# ESP32-C61 register map
Vendor: ESPRESSIF SYSTEMS (SHANGHAI) CO., LTD.; Series: ESP32 C-Series; File version: 1
CPU: RV32IMAC r0p0, little endian, no MPU, no FPU, 0 interrupt priority bits
Address unit: 32 bits
Registers are 32-bit, read-write, reset 0x0 unless marked. A register's access mark holds for its fields unless they carry their own. Offsets are from the block's base; [hi:lo] are bit positions; lines under a group give offsets from that group; {n}, {i} and the like mark numbered series.

## SOC_ETM — Event Task Matrix
Base 0x60013000
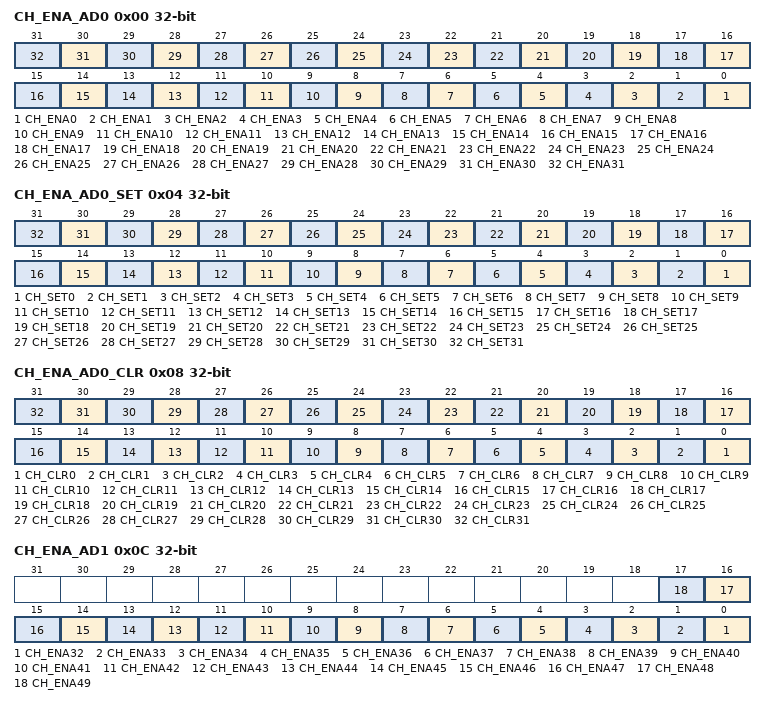
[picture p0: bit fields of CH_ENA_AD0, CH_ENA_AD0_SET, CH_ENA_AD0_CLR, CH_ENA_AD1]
0x00 CH_ENA_AD0 — Channel enable status register
  [n] CH_ENA{n} (n=0..31) — Represents ch{n} enable status.\\0: Disable\\1: Enable
0x04 CH_ENA_AD0_SET wo — Channel enable set register
  [n] CH_SET{n} (n=0..31) — Configures whether or not to enable ch{n}.\\0: Invalid, No effect\\1: Enable
0x08 CH_ENA_AD0_CLR wo — Channel enable clear register
  [n] CH_CLR{n} (n=0..31) — Configures whether or not to clear ch{n} enable.\\0: Invalid, No effect\\1: Clear
0x0C CH_ENA_AD1 — Channel enable status register
  [n-32] CH_ENA{n} (n=32..49) — Represents ch{n} enable status.\\0: Disable\\1: Enable
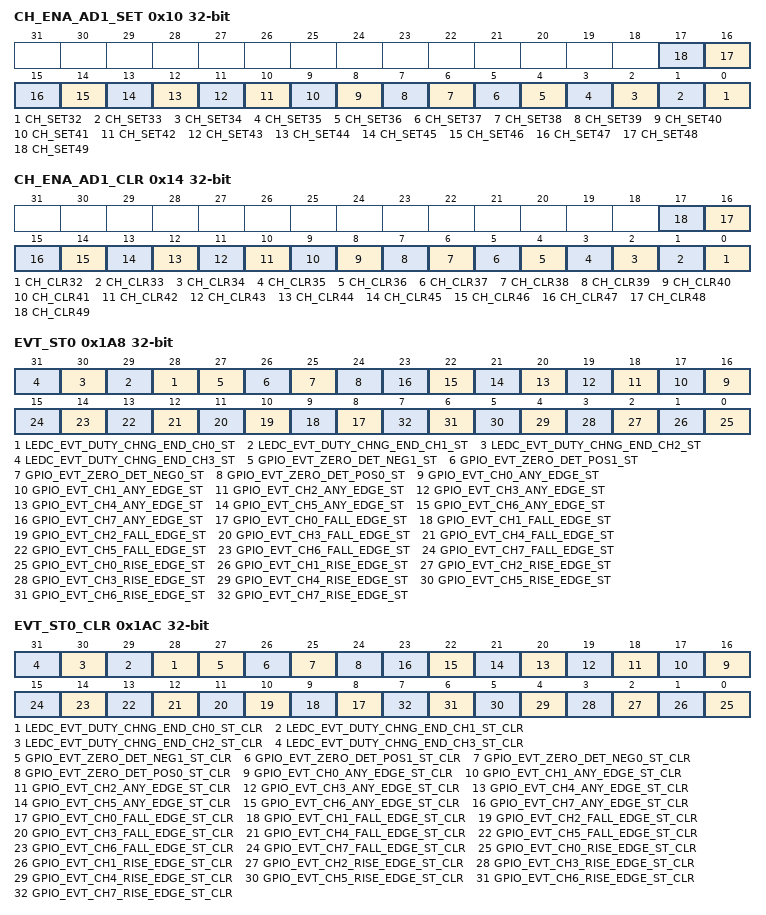
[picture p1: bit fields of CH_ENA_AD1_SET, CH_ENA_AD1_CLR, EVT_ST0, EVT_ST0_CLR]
0x10 CH_ENA_AD1_SET wo — Channel enable set register
  [n-32] CH_SET{n} (n=32..49) — Configures whether or not to enable ch{n}.\\0: Invalid, No effect\\1: Enable
0x14 CH_ENA_AD1_CLR wo — Channel enable clear register
  [n-32] CH_CLR{n} (n=32..49) — Configures whether or not to clear ch{n} enable.\\0: Invalid, No effect\\1: Clear
{0x18+8i} CH{i} (i=0..49) group — Cluster CH{i}, containing CH*_EVT_ID, CH*_TASK_ID
  0x00 EVT_ID — Channel0 event id register
    [6:0] EVT_ID — Configures ch0_evt_id
  0x04 TASK_ID — Channel0 task id register
    [7:0] TASK_ID — Configures ch0_task_id
0x1A8 EVT_ST0 — Events trigger status register
  [n+28] LEDC_EVT_DUTY_CHNG_END_CH{n}_ST (n=0..3) — Represents LEDC_evt_duty_chng_end_ch{n} trigger status.\\0: Not triggered\\1: Triggered
  [27] GPIO_EVT_ZERO_DET_NEG1_ST — Represents GPIO_evt_zero_det_neg1 trigger status.\\0: Not triggered\\1: Triggered
  [26] GPIO_EVT_ZERO_DET_POS1_ST — Represents GPIO_evt_zero_det_pos1 trigger status.\\0: Not triggered\\1: Triggered
  [25] GPIO_EVT_ZERO_DET_NEG0_ST — Represents GPIO_evt_zero_det_neg0 trigger status.\\0: Not triggered\\1: Triggered
  [24] GPIO_EVT_ZERO_DET_POS0_ST — Represents GPIO_evt_zero_det_pos0 trigger status.\\0: Not triggered\\1: Triggered
  [n+16] GPIO_EVT_CH{n}_ANY_EDGE_ST (n=0..7) — Represents GPIO_evt_ch{n}_any_edge trigger status.\\0: Not triggered\\1: Triggered
  [n+8] GPIO_EVT_CH{n}_FALL_EDGE_ST (n=0..7) — Represents GPIO_evt_ch{n}_fall_edge trigger status.\\0: Not triggered\\1: Triggered
  [n] GPIO_EVT_CH{n}_RISE_EDGE_ST (n=0..7) — Represents GPIO_evt_ch{n}_rise_edge trigger status.\\0: Not triggered\\1: Triggered
0x1AC EVT_ST0_CLR wo — Events trigger status clear register
  [n+28] LEDC_EVT_DUTY_CHNG_END_CH{n}_ST_CLR (n=0..3) — Configures whether or not to clear LEDC_evt_duty_chng_end_ch{n} trigger status.\\0: Invalid, No effect\\1: Clear
  [27] GPIO_EVT_ZERO_DET_NEG1_ST_CLR — Configures whether or not to clear GPIO_evt_zero_det_neg1 trigger status.\\0: Invalid, No effect\\1: Clear
  [26] GPIO_EVT_ZERO_DET_POS1_ST_CLR — Configures whether or not to clear GPIO_evt_zero_det_pos1 trigger status.\\0: Invalid, No effect\\1: Clear
  [25] GPIO_EVT_ZERO_DET_NEG0_ST_CLR — Configures whether or not to clear GPIO_evt_zero_det_neg0 trigger status.\\0: Invalid, No effect\\1: Clear
  [24] GPIO_EVT_ZERO_DET_POS0_ST_CLR — Configures whether or not to clear GPIO_evt_zero_det_pos0 trigger status.\\0: Invalid, No effect\\1: Clear
  [n+16] GPIO_EVT_CH{n}_ANY_EDGE_ST_CLR (n=0..7) — Configures whether or not to clear GPIO_evt_ch{n}_any_edge trigger status.\\0: Invalid, No effect\\1: Clear
  [n+8] GPIO_EVT_CH{n}_FALL_EDGE_ST_CLR (n=0..7) — Configures whether or not to clear GPIO_evt_ch{n}_fall_edge trigger status.\\0: Invalid, No effect\\1: Clear
  [n] GPIO_EVT_CH{n}_RISE_EDGE_ST_CLR (n=0..7) — Configures whether or not to clear GPIO_evt_ch{n}_rise_edge trigger status.\\0: Invalid, No effect\\1: Clear
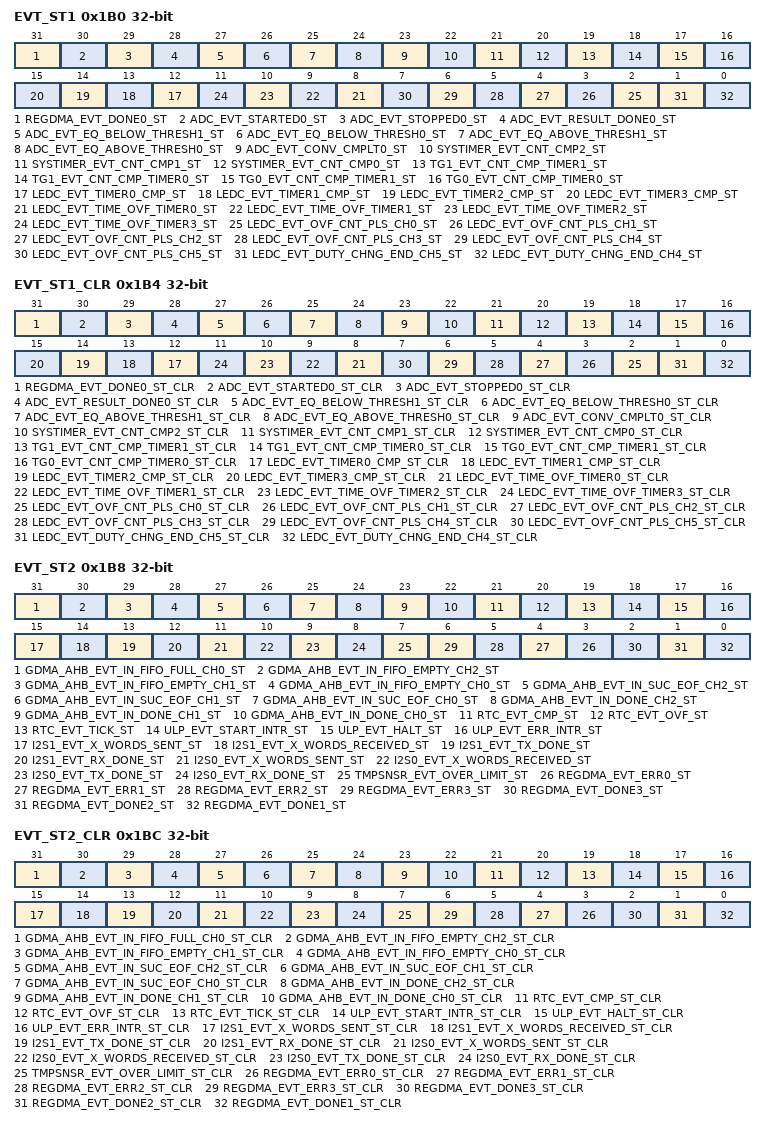
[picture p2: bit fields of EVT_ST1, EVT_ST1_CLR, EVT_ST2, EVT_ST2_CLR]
0x1B0 EVT_ST1 — Events trigger status register
  [31] REGDMA_EVT_DONE0_ST — Represents REGDMA_evt_done0 trigger status.\\0: Not triggered\\1: Triggered
  [30] ADC_EVT_STARTED0_ST — Represents ADC_evt_started0 trigger status.\\0: Not triggered\\1: Triggered
  [29] ADC_EVT_STOPPED0_ST — Represents ADC_evt_stopped0 trigger status.\\0: Not triggered\\1: Triggered
  [28] ADC_EVT_RESULT_DONE0_ST — Represents ADC_evt_result_done0 trigger status.\\0: Not triggered\\1: Triggered
  [27] ADC_EVT_EQ_BELOW_THRESH1_ST — Represents ADC_evt_eq_below_thresh1 trigger status.\\0: Not triggered\\1: Triggered
  [26] ADC_EVT_EQ_BELOW_THRESH0_ST — Represents ADC_evt_eq_below_thresh0 trigger status.\\0: Not triggered\\1: Triggered
  [25] ADC_EVT_EQ_ABOVE_THRESH1_ST — Represents ADC_evt_eq_above_thresh1 trigger status.\\0: Not triggered\\1: Triggered
  [24] ADC_EVT_EQ_ABOVE_THRESH0_ST — Represents ADC_evt_eq_above_thresh0 trigger status.\\0: Not triggered\\1: Triggered
  [23] ADC_EVT_CONV_CMPLT0_ST — Represents ADC_evt_conv_cmplt0 trigger status.\\0: Not triggered\\1: Triggered
  [22] SYSTIMER_EVT_CNT_CMP2_ST — Represents SYSTIMER_evt_cnt_cmp2 trigger status.\\0: Not triggered\\1: Triggered
  [21] SYSTIMER_EVT_CNT_CMP1_ST — Represents SYSTIMER_evt_cnt_cmp1 trigger status.\\0: Not triggered\\1: Triggered
  [20] SYSTIMER_EVT_CNT_CMP0_ST — Represents SYSTIMER_evt_cnt_cmp0 trigger status.\\0: Not triggered\\1: Triggered
  [19] TG1_EVT_CNT_CMP_TIMER1_ST — Represents TG1_evt_cnt_cmp_timer1 trigger status.\\0: Not triggered\\1: Triggered
  [18] TG1_EVT_CNT_CMP_TIMER0_ST — Represents TG1_evt_cnt_cmp_timer0 trigger status.\\0: Not triggered\\1: Triggered
  [17] TG0_EVT_CNT_CMP_TIMER1_ST — Represents TG0_evt_cnt_cmp_timer1 trigger status.\\0: Not triggered\\1: Triggered
  [16] TG0_EVT_CNT_CMP_TIMER0_ST — Represents TG0_evt_cnt_cmp_timer0 trigger status.\\0: Not triggered\\1: Triggered
  [n+12] LEDC_EVT_TIMER{n}_CMP_ST (n=0..3) — Represents LEDC_evt_timer{n}_cmp trigger status.\\0: Not triggered\\1: Triggered
  [n+8] LEDC_EVT_TIME_OVF_TIMER{n}_ST (n=0..3) — Represents LEDC_evt_time_ovf_timer{n} trigger status.\\0: Not triggered\\1: Triggered
  [n+2] LEDC_EVT_OVF_CNT_PLS_CH{n}_ST (n=0..5) — Represents LEDC_evt_ovf_cnt_pls_ch{n} trigger status.\\0: Not triggered\\1: Triggered
  [1] LEDC_EVT_DUTY_CHNG_END_CH5_ST — Represents LEDC_evt_duty_chng_end_ch5 trigger status.\\0: Not triggered\\1: Triggered
  [0] LEDC_EVT_DUTY_CHNG_END_CH4_ST — Represents LEDC_evt_duty_chng_end_ch4 trigger status.\\0: Not triggered\\1: Triggered
0x1B4 EVT_ST1_CLR wo — Events trigger status clear register
  [31] REGDMA_EVT_DONE0_ST_CLR — Configures whether or not to clear REGDMA_evt_done0 trigger status.\\0: Invalid, No effect\\1: Clear
  [30] ADC_EVT_STARTED0_ST_CLR — Configures whether or not to clear ADC_evt_started0 trigger status.\\0: Invalid, No effect\\1: Clear
  [29] ADC_EVT_STOPPED0_ST_CLR — Configures whether or not to clear ADC_evt_stopped0 trigger status.\\0: Invalid, No effect\\1: Clear
  [28] ADC_EVT_RESULT_DONE0_ST_CLR — Configures whether or not to clear ADC_evt_result_done0 trigger status.\\0: Invalid, No effect\\1: Clear
  [27] ADC_EVT_EQ_BELOW_THRESH1_ST_CLR — Configures whether or not to clear ADC_evt_eq_below_thresh1 trigger status.\\0: Invalid, No effect\\1: Clear
  [26] ADC_EVT_EQ_BELOW_THRESH0_ST_CLR — Configures whether or not to clear ADC_evt_eq_below_thresh0 trigger status.\\0: Invalid, No effect\\1: Clear
  [25] ADC_EVT_EQ_ABOVE_THRESH1_ST_CLR — Configures whether or not to clear ADC_evt_eq_above_thresh1 trigger status.\\0: Invalid, No effect\\1: Clear
  [24] ADC_EVT_EQ_ABOVE_THRESH0_ST_CLR — Configures whether or not to clear ADC_evt_eq_above_thresh0 trigger status.\\0: Invalid, No effect\\1: Clear
  [23] ADC_EVT_CONV_CMPLT0_ST_CLR — Configures whether or not to clear ADC_evt_conv_cmplt0 trigger status.\\0: Invalid, No effect\\1: Clear
  [22] SYSTIMER_EVT_CNT_CMP2_ST_CLR — Configures whether or not to clear SYSTIMER_evt_cnt_cmp2 trigger status.\\0: Invalid, No effect\\1: Clear
  [21] SYSTIMER_EVT_CNT_CMP1_ST_CLR — Configures whether or not to clear SYSTIMER_evt_cnt_cmp1 trigger status.\\0: Invalid, No effect\\1: Clear
  [20] SYSTIMER_EVT_CNT_CMP0_ST_CLR — Configures whether or not to clear SYSTIMER_evt_cnt_cmp0 trigger status.\\0: Invalid, No effect\\1: Clear
  [19] TG1_EVT_CNT_CMP_TIMER1_ST_CLR — Configures whether or not to clear TG1_evt_cnt_cmp_timer1 trigger status.\\0: Invalid, No effect\\1: Clear
  [18] TG1_EVT_CNT_CMP_TIMER0_ST_CLR — Configures whether or not to clear TG1_evt_cnt_cmp_timer0 trigger status.\\0: Invalid, No effect\\1: Clear
  [17] TG0_EVT_CNT_CMP_TIMER1_ST_CLR — Configures whether or not to clear TG0_evt_cnt_cmp_timer1 trigger status.\\0: Invalid, No effect\\1: Clear
  [16] TG0_EVT_CNT_CMP_TIMER0_ST_CLR — Configures whether or not to clear TG0_evt_cnt_cmp_timer0 trigger status.\\0: Invalid, No effect\\1: Clear
  [n+12] LEDC_EVT_TIMER{n}_CMP_ST_CLR (n=0..3) — Configures whether or not to clear LEDC_evt_timer{n}_cmp trigger status.\\0: Invalid, No effect\\1: Clear
  [n+8] LEDC_EVT_TIME_OVF_TIMER{n}_ST_CLR (n=0..3) — Configures whether or not to clear LEDC_evt_time_ovf_timer{n} trigger status.\\0: Invalid, No effect\\1: Clear
  [n+2] LEDC_EVT_OVF_CNT_PLS_CH{n}_ST_CLR (n=0..5) — Configures whether or not to clear LEDC_evt_ovf_cnt_pls_ch{n} trigger status.\\0: Invalid, No effect\\1: Clear
  [1] LEDC_EVT_DUTY_CHNG_END_CH5_ST_CLR — Configures whether or not to clear LEDC_evt_duty_chng_end_ch5 trigger status.\\0: Invalid, No effect\\1: Clear
  [0] LEDC_EVT_DUTY_CHNG_END_CH4_ST_CLR — Configures whether or not to clear LEDC_evt_duty_chng_end_ch4 trigger status.\\0: Invalid, No effect\\1: Clear
0x1B8 EVT_ST2 — Events trigger status register
  [31] GDMA_AHB_EVT_IN_FIFO_FULL_CH0_ST — Represents GDMA_AHB_evt_in_fifo_full_ch0 trigger status.\\0: Not triggered\\1: Triggered
  [30] GDMA_AHB_EVT_IN_FIFO_EMPTY_CH2_ST — Represents GDMA_AHB_evt_in_fifo_empty_ch2 trigger status.\\0: Not triggered\\1: Triggered
  [29] GDMA_AHB_EVT_IN_FIFO_EMPTY_CH1_ST — Represents GDMA_AHB_evt_in_fifo_empty_ch1 trigger status.\\0: Not triggered\\1: Triggered
  [28] GDMA_AHB_EVT_IN_FIFO_EMPTY_CH0_ST — Represents GDMA_AHB_evt_in_fifo_empty_ch0 trigger status.\\0: Not triggered\\1: Triggered
  [27] GDMA_AHB_EVT_IN_SUC_EOF_CH2_ST — Represents GDMA_AHB_evt_in_suc_eof_ch2 trigger status.\\0: Not triggered\\1: Triggered
  [26] GDMA_AHB_EVT_IN_SUC_EOF_CH1_ST — Represents GDMA_AHB_evt_in_suc_eof_ch1 trigger status.\\0: Not triggered\\1: Triggered
  [25] GDMA_AHB_EVT_IN_SUC_EOF_CH0_ST — Represents GDMA_AHB_evt_in_suc_eof_ch0 trigger status.\\0: Not triggered\\1: Triggered
  [24] GDMA_AHB_EVT_IN_DONE_CH2_ST — Represents GDMA_AHB_evt_in_done_ch2 trigger status.\\0: Not triggered\\1: Triggered
  [23] GDMA_AHB_EVT_IN_DONE_CH1_ST — Represents GDMA_AHB_evt_in_done_ch1 trigger status.\\0: Not triggered\\1: Triggered
  [22] GDMA_AHB_EVT_IN_DONE_CH0_ST — Represents GDMA_AHB_evt_in_done_ch0 trigger status.\\0: Not triggered\\1: Triggered
  [21] RTC_EVT_CMP_ST — Represents RTC_evt_cmp trigger status.\\0: Not triggered\\1: Triggered
  [20] RTC_EVT_OVF_ST — Represents RTC_evt_ovf trigger status.\\0: Not triggered\\1: Triggered
  [19] RTC_EVT_TICK_ST — Represents RTC_evt_tick trigger status.\\0: Not triggered\\1: Triggered
  [18] ULP_EVT_START_INTR_ST — Represents ULP_evt_start_intr trigger status.\\0: Not triggered\\1: Triggered
  [17] ULP_EVT_HALT_ST — Represents ULP_evt_halt trigger status.\\0: Not triggered\\1: Triggered
  [16] ULP_EVT_ERR_INTR_ST — Represents ULP_evt_err_intr trigger status.\\0: Not triggered\\1: Triggered
  [15] I2S1_EVT_X_WORDS_SENT_ST — Represents I2S1_evt_x_words_sent trigger status.\\0: Not triggered\\1: Triggered
  [14] I2S1_EVT_X_WORDS_RECEIVED_ST — Represents I2S1_evt_x_words_received trigger status.\\0: Not triggered\\1: Triggered
  [13] I2S1_EVT_TX_DONE_ST — Represents I2S1_evt_tx_done trigger status.\\0: Not triggered\\1: Triggered
  [12] I2S1_EVT_RX_DONE_ST — Represents I2S1_evt_rx_done trigger status.\\0: Not triggered\\1: Triggered
  [11] I2S0_EVT_X_WORDS_SENT_ST — Represents I2S0_evt_x_words_sent trigger status.\\0: Not triggered\\1: Triggered
  [10] I2S0_EVT_X_WORDS_RECEIVED_ST — Represents I2S0_evt_x_words_received trigger status.\\0: Not triggered\\1: Triggered
  [9] I2S0_EVT_TX_DONE_ST — Represents I2S0_evt_tx_done trigger status.\\0: Not triggered\\1: Triggered
  [8] I2S0_EVT_RX_DONE_ST — Represents I2S0_evt_rx_done trigger status.\\0: Not triggered\\1: Triggered
  [7] TMPSNSR_EVT_OVER_LIMIT_ST — Represents TMPSNSR_evt_over_limit trigger status.\\0: Not triggered\\1: Triggered
  [n+3] REGDMA_EVT_ERR{n}_ST (n=0..3) — Represents REGDMA_evt_err{n} trigger status.\\0: Not triggered\\1: Triggered
  [2] REGDMA_EVT_DONE3_ST — Represents REGDMA_evt_done3 trigger status.\\0: Not triggered\\1: Triggered
  [1] REGDMA_EVT_DONE2_ST — Represents REGDMA_evt_done2 trigger status.\\0: Not triggered\\1: Triggered
  [0] REGDMA_EVT_DONE1_ST — Represents REGDMA_evt_done1 trigger status.\\0: Not triggered\\1: Triggered
0x1BC EVT_ST2_CLR wo — Events trigger status clear register
  [31] GDMA_AHB_EVT_IN_FIFO_FULL_CH0_ST_CLR — Configures whether or not to clear GDMA_AHB_evt_in_fifo_full_ch0 trigger status.\\0: Invalid, No effect\\1: Clear
  [30] GDMA_AHB_EVT_IN_FIFO_EMPTY_CH2_ST_CLR — Configures whether or not to clear GDMA_AHB_evt_in_fifo_empty_ch2 trigger status.\\0: Invalid, No effect\\1: Clear
  [29] GDMA_AHB_EVT_IN_FIFO_EMPTY_CH1_ST_CLR — Configures whether or not to clear GDMA_AHB_evt_in_fifo_empty_ch1 trigger status.\\0: Invalid, No effect\\1: Clear
  [28] GDMA_AHB_EVT_IN_FIFO_EMPTY_CH0_ST_CLR — Configures whether or not to clear GDMA_AHB_evt_in_fifo_empty_ch0 trigger status.\\0: Invalid, No effect\\1: Clear
  [27] GDMA_AHB_EVT_IN_SUC_EOF_CH2_ST_CLR — Configures whether or not to clear GDMA_AHB_evt_in_suc_eof_ch2 trigger status.\\0: Invalid, No effect\\1: Clear
  [26] GDMA_AHB_EVT_IN_SUC_EOF_CH1_ST_CLR — Configures whether or not to clear GDMA_AHB_evt_in_suc_eof_ch1 trigger status.\\0: Invalid, No effect\\1: Clear
  [25] GDMA_AHB_EVT_IN_SUC_EOF_CH0_ST_CLR — Configures whether or not to clear GDMA_AHB_evt_in_suc_eof_ch0 trigger status.\\0: Invalid, No effect\\1: Clear
  [24] GDMA_AHB_EVT_IN_DONE_CH2_ST_CLR — Configures whether or not to clear GDMA_AHB_evt_in_done_ch2 trigger status.\\0: Invalid, No effect\\1: Clear
  [23] GDMA_AHB_EVT_IN_DONE_CH1_ST_CLR — Configures whether or not to clear GDMA_AHB_evt_in_done_ch1 trigger status.\\0: Invalid, No effect\\1: Clear
  [22] GDMA_AHB_EVT_IN_DONE_CH0_ST_CLR — Configures whether or not to clear GDMA_AHB_evt_in_done_ch0 trigger status.\\0: Invalid, No effect\\1: Clear
  [21] RTC_EVT_CMP_ST_CLR — Configures whether or not to clear RTC_evt_cmp trigger status.\\0: Invalid, No effect\\1: Clear
  [20] RTC_EVT_OVF_ST_CLR — Configures whether or not to clear RTC_evt_ovf trigger status.\\0: Invalid, No effect\\1: Clear
  [19] RTC_EVT_TICK_ST_CLR — Configures whether or not to clear RTC_evt_tick trigger status.\\0: Invalid, No effect\\1: Clear
  [18] ULP_EVT_START_INTR_ST_CLR — Configures whether or not to clear ULP_evt_start_intr trigger status.\\0: Invalid, No effect\\1: Clear
  [17] ULP_EVT_HALT_ST_CLR — Configures whether or not to clear ULP_evt_halt trigger status.\\0: Invalid, No effect\\1: Clear
  [16] ULP_EVT_ERR_INTR_ST_CLR — Configures whether or not to clear ULP_evt_err_intr trigger status.\\0: Invalid, No effect\\1: Clear
  [15] I2S1_EVT_X_WORDS_SENT_ST_CLR — Configures whether or not to clear I2S1_evt_x_words_sent trigger status.\\0: Invalid, No effect\\1: Clear
  [14] I2S1_EVT_X_WORDS_RECEIVED_ST_CLR — Configures whether or not to clear I2S1_evt_x_words_received trigger status.\\0: Invalid, No effect\\1: Clear
  [13] I2S1_EVT_TX_DONE_ST_CLR — Configures whether or not to clear I2S1_evt_tx_done trigger status.\\0: Invalid, No effect\\1: Clear
  [12] I2S1_EVT_RX_DONE_ST_CLR — Configures whether or not to clear I2S1_evt_rx_done trigger status.\\0: Invalid, No effect\\1: Clear
  [11] I2S0_EVT_X_WORDS_SENT_ST_CLR — Configures whether or not to clear I2S0_evt_x_words_sent trigger status.\\0: Invalid, No effect\\1: Clear
  [10] I2S0_EVT_X_WORDS_RECEIVED_ST_CLR — Configures whether or not to clear I2S0_evt_x_words_received trigger status.\\0: Invalid, No effect\\1: Clear
  [9] I2S0_EVT_TX_DONE_ST_CLR — Configures whether or not to clear I2S0_evt_tx_done trigger status.\\0: Invalid, No effect\\1: Clear
  [8] I2S0_EVT_RX_DONE_ST_CLR — Configures whether or not to clear I2S0_evt_rx_done trigger status.\\0: Invalid, No effect\\1: Clear
  [7] TMPSNSR_EVT_OVER_LIMIT_ST_CLR — Configures whether or not to clear TMPSNSR_evt_over_limit trigger status.\\0: Invalid, No effect\\1: Clear
  [n+3] REGDMA_EVT_ERR{n}_ST_CLR (n=0..3) — Configures whether or not to clear REGDMA_evt_err{n} trigger status.\\0: Invalid, No effect\\1: Clear
  [2] REGDMA_EVT_DONE3_ST_CLR — Configures whether or not to clear REGDMA_evt_done3 trigger status.\\0: Invalid, No effect\\1: Clear
  [1] REGDMA_EVT_DONE2_ST_CLR — Configures whether or not to clear REGDMA_evt_done2 trigger status.\\0: Invalid, No effect\\1: Clear
  [0] REGDMA_EVT_DONE1_ST_CLR — Configures whether or not to clear REGDMA_evt_done1 trigger status.\\0: Invalid, No effect\\1: Clear
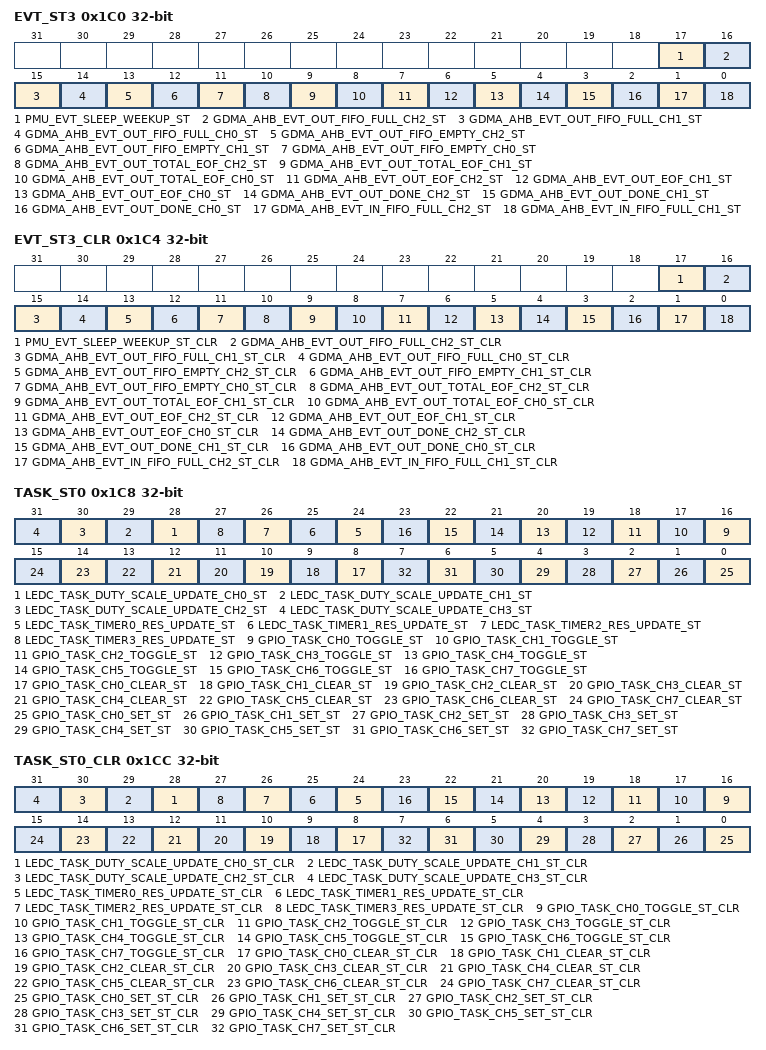
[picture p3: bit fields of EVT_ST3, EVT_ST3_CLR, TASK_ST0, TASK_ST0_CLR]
0x1C0 EVT_ST3 — Events trigger status register
  [17] PMU_EVT_SLEEP_WEEKUP_ST — Represents PMU_evt_sleep_weekup trigger status.\\0: Not triggered\\1: Triggered
  [16] GDMA_AHB_EVT_OUT_FIFO_FULL_CH2_ST — Represents GDMA_AHB_evt_out_fifo_full_ch2 trigger status.\\0: Not triggered\\1: Triggered
  [15] GDMA_AHB_EVT_OUT_FIFO_FULL_CH1_ST — Represents GDMA_AHB_evt_out_fifo_full_ch1 trigger status.\\0: Not triggered\\1: Triggered
  [14] GDMA_AHB_EVT_OUT_FIFO_FULL_CH0_ST — Represents GDMA_AHB_evt_out_fifo_full_ch0 trigger status.\\0: Not triggered\\1: Triggered
  [13] GDMA_AHB_EVT_OUT_FIFO_EMPTY_CH2_ST — Represents GDMA_AHB_evt_out_fifo_empty_ch2 trigger status.\\0: Not triggered\\1: Triggered
  [12] GDMA_AHB_EVT_OUT_FIFO_EMPTY_CH1_ST — Represents GDMA_AHB_evt_out_fifo_empty_ch1 trigger status.\\0: Not triggered\\1: Triggered
  [11] GDMA_AHB_EVT_OUT_FIFO_EMPTY_CH0_ST — Represents GDMA_AHB_evt_out_fifo_empty_ch0 trigger status.\\0: Not triggered\\1: Triggered
  [10] GDMA_AHB_EVT_OUT_TOTAL_EOF_CH2_ST — Represents GDMA_AHB_evt_out_total_eof_ch2 trigger status.\\0: Not triggered\\1: Triggered
  [9] GDMA_AHB_EVT_OUT_TOTAL_EOF_CH1_ST — Represents GDMA_AHB_evt_out_total_eof_ch1 trigger status.\\0: Not triggered\\1: Triggered
  [8] GDMA_AHB_EVT_OUT_TOTAL_EOF_CH0_ST — Represents GDMA_AHB_evt_out_total_eof_ch0 trigger status.\\0: Not triggered\\1: Triggered
  [7] GDMA_AHB_EVT_OUT_EOF_CH2_ST — Represents GDMA_AHB_evt_out_eof_ch2 trigger status.\\0: Not triggered\\1: Triggered
  [6] GDMA_AHB_EVT_OUT_EOF_CH1_ST — Represents GDMA_AHB_evt_out_eof_ch1 trigger status.\\0: Not triggered\\1: Triggered
  [5] GDMA_AHB_EVT_OUT_EOF_CH0_ST — Represents GDMA_AHB_evt_out_eof_ch0 trigger status.\\0: Not triggered\\1: Triggered
  [4] GDMA_AHB_EVT_OUT_DONE_CH2_ST — Represents GDMA_AHB_evt_out_done_ch2 trigger status.\\0: Not triggered\\1: Triggered
  [3] GDMA_AHB_EVT_OUT_DONE_CH1_ST — Represents GDMA_AHB_evt_out_done_ch1 trigger status.\\0: Not triggered\\1: Triggered
  [2] GDMA_AHB_EVT_OUT_DONE_CH0_ST — Represents GDMA_AHB_evt_out_done_ch0 trigger status.\\0: Not triggered\\1: Triggered
  [1] GDMA_AHB_EVT_IN_FIFO_FULL_CH2_ST — Represents GDMA_AHB_evt_in_fifo_full_ch2 trigger status.\\0: Not triggered\\1: Triggered
  [0] GDMA_AHB_EVT_IN_FIFO_FULL_CH1_ST — Represents GDMA_AHB_evt_in_fifo_full_ch1 trigger status.\\0: Not triggered\\1: Triggered
0x1C4 EVT_ST3_CLR wo — Events trigger status clear register
  [17] PMU_EVT_SLEEP_WEEKUP_ST_CLR — Configures whether or not to clear PMU_evt_sleep_weekup trigger status.\\0: Invalid, No effect\\1: Clear
  [16] GDMA_AHB_EVT_OUT_FIFO_FULL_CH2_ST_CLR — Configures whether or not to clear GDMA_AHB_evt_out_fifo_full_ch2 trigger status.\\0: Invalid, No effect\\1: Clear
  [15] GDMA_AHB_EVT_OUT_FIFO_FULL_CH1_ST_CLR — Configures whether or not to clear GDMA_AHB_evt_out_fifo_full_ch1 trigger status.\\0: Invalid, No effect\\1: Clear
  [14] GDMA_AHB_EVT_OUT_FIFO_FULL_CH0_ST_CLR — Configures whether or not to clear GDMA_AHB_evt_out_fifo_full_ch0 trigger status.\\0: Invalid, No effect\\1: Clear
  [13] GDMA_AHB_EVT_OUT_FIFO_EMPTY_CH2_ST_CLR — Configures whether or not to clear GDMA_AHB_evt_out_fifo_empty_ch2 trigger status.\\0: Invalid, No effect\\1: Clear
  [12] GDMA_AHB_EVT_OUT_FIFO_EMPTY_CH1_ST_CLR — Configures whether or not to clear GDMA_AHB_evt_out_fifo_empty_ch1 trigger status.\\0: Invalid, No effect\\1: Clear
  [11] GDMA_AHB_EVT_OUT_FIFO_EMPTY_CH0_ST_CLR — Configures whether or not to clear GDMA_AHB_evt_out_fifo_empty_ch0 trigger status.\\0: Invalid, No effect\\1: Clear
  [10] GDMA_AHB_EVT_OUT_TOTAL_EOF_CH2_ST_CLR — Configures whether or not to clear GDMA_AHB_evt_out_total_eof_ch2 trigger status.\\0: Invalid, No effect\\1: Clear
  [9] GDMA_AHB_EVT_OUT_TOTAL_EOF_CH1_ST_CLR — Configures whether or not to clear GDMA_AHB_evt_out_total_eof_ch1 trigger status.\\0: Invalid, No effect\\1: Clear
  [8] GDMA_AHB_EVT_OUT_TOTAL_EOF_CH0_ST_CLR — Configures whether or not to clear GDMA_AHB_evt_out_total_eof_ch0 trigger status.\\0: Invalid, No effect\\1: Clear
  [7] GDMA_AHB_EVT_OUT_EOF_CH2_ST_CLR — Configures whether or not to clear GDMA_AHB_evt_out_eof_ch2 trigger status.\\0: Invalid, No effect\\1: Clear
  [6] GDMA_AHB_EVT_OUT_EOF_CH1_ST_CLR — Configures whether or not to clear GDMA_AHB_evt_out_eof_ch1 trigger status.\\0: Invalid, No effect\\1: Clear
  [5] GDMA_AHB_EVT_OUT_EOF_CH0_ST_CLR — Configures whether or not to clear GDMA_AHB_evt_out_eof_ch0 trigger status.\\0: Invalid, No effect\\1: Clear
  [4] GDMA_AHB_EVT_OUT_DONE_CH2_ST_CLR — Configures whether or not to clear GDMA_AHB_evt_out_done_ch2 trigger status.\\0: Invalid, No effect\\1: Clear
  [3] GDMA_AHB_EVT_OUT_DONE_CH1_ST_CLR — Configures whether or not to clear GDMA_AHB_evt_out_done_ch1 trigger status.\\0: Invalid, No effect\\1: Clear
  [2] GDMA_AHB_EVT_OUT_DONE_CH0_ST_CLR — Configures whether or not to clear GDMA_AHB_evt_out_done_ch0 trigger status.\\0: Invalid, No effect\\1: Clear
  [1] GDMA_AHB_EVT_IN_FIFO_FULL_CH2_ST_CLR — Configures whether or not to clear GDMA_AHB_evt_in_fifo_full_ch2 trigger status.\\0: Invalid, No effect\\1: Clear
  [0] GDMA_AHB_EVT_IN_FIFO_FULL_CH1_ST_CLR — Configures whether or not to clear GDMA_AHB_evt_in_fifo_full_ch1 trigger status.\\0: Invalid, No effect\\1: Clear
0x1C8 TASK_ST0 — Tasks trigger status register
  [n+28] LEDC_TASK_DUTY_SCALE_UPDATE_CH{n}_ST (n=0..3) — Represents LEDC_task_duty_scale_update_ch{n} trigger status.\\0: Not triggered\\1: Triggered
  [n+24] LEDC_TASK_TIMER{n}_RES_UPDATE_ST (n=0..3) — Represents LEDC_task_timer{n}_res_update trigger status.\\0: Not triggered\\1: Triggered
  [n+16] GPIO_TASK_CH{n}_TOGGLE_ST (n=0..7) — Represents GPIO_task_ch{n}_toggle trigger status.\\0: Not triggered\\1: Triggered
  [n+8] GPIO_TASK_CH{n}_CLEAR_ST (n=0..7) — Represents GPIO_task_ch{n}_clear trigger status.\\0: Not triggered\\1: Triggered
  [n] GPIO_TASK_CH{n}_SET_ST (n=0..7) — Represents GPIO_task_ch{n}_set trigger status.\\0: Not triggered\\1: Triggered
0x1CC TASK_ST0_CLR wo — Tasks trigger status clear register
  [n+28] LEDC_TASK_DUTY_SCALE_UPDATE_CH{n}_ST_CLR (n=0..3) — Configures whether or not to clear LEDC_task_duty_scale_update_ch{n} trigger status.\\0: Invalid, No effect\\1: Clear
  [n+24] LEDC_TASK_TIMER{n}_RES_UPDATE_ST_CLR (n=0..3) — Configures whether or not to clear LEDC_task_timer{n}_res_update trigger status.\\0: Invalid, No effect\\1: Clear
  [n+16] GPIO_TASK_CH{n}_TOGGLE_ST_CLR (n=0..7) — Configures whether or not to clear GPIO_task_ch{n}_toggle trigger status.\\0: Invalid, No effect\\1: Clear
  [n+8] GPIO_TASK_CH{n}_CLEAR_ST_CLR (n=0..7) — Configures whether or not to clear GPIO_task_ch{n}_clear trigger status.\\0: Invalid, No effect\\1: Clear
  [n] GPIO_TASK_CH{n}_SET_ST_CLR (n=0..7) — Configures whether or not to clear GPIO_task_ch{n}_set trigger status.\\0: Invalid, No effect\\1: Clear
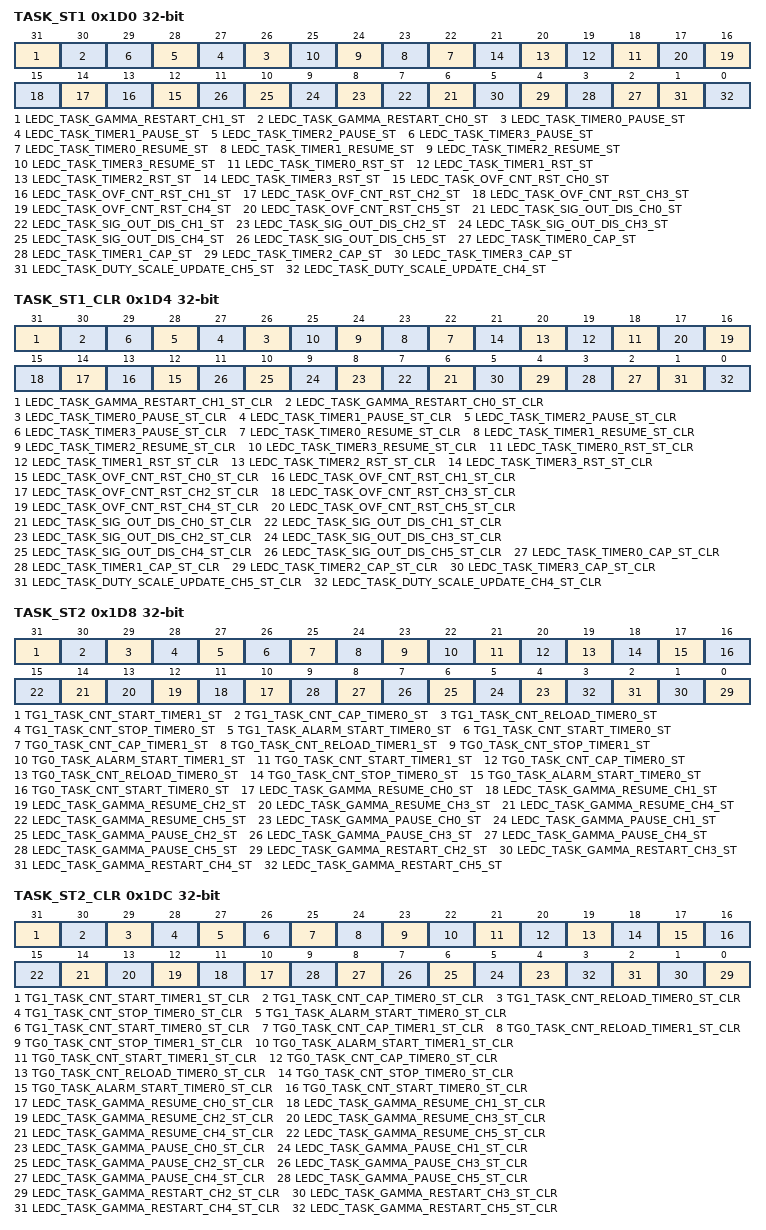
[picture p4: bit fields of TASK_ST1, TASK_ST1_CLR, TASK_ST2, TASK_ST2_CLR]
0x1D0 TASK_ST1 — Tasks trigger status register
  [31] LEDC_TASK_GAMMA_RESTART_CH1_ST — Represents LEDC_task_gamma_restart_ch1 trigger status.\\0: Not triggered\\1: Triggered
  [30] LEDC_TASK_GAMMA_RESTART_CH0_ST — Represents LEDC_task_gamma_restart_ch0 trigger status.\\0: Not triggered\\1: Triggered
  [n+26] LEDC_TASK_TIMER{n}_PAUSE_ST (n=0..3) — Represents LEDC_task_timer{n}_pause trigger status.\\0: Not triggered\\1: Triggered
  [n+22] LEDC_TASK_TIMER{n}_RESUME_ST (n=0..3) — Represents LEDC_task_timer{n}_resume trigger status.\\0: Not triggered\\1: Triggered
  [n+18] LEDC_TASK_TIMER{n}_RST_ST (n=0..3) — Represents LEDC_task_timer{n}_rst trigger status.\\0: Not triggered\\1: Triggered
  [n+12] LEDC_TASK_OVF_CNT_RST_CH{n}_ST (n=0..5) — Represents LEDC_task_ovf_cnt_rst_ch{n} trigger status.\\0: Not triggered\\1: Triggered
  [n+6] LEDC_TASK_SIG_OUT_DIS_CH{n}_ST (n=0..5) — Represents LEDC_task_sig_out_dis_ch{n} trigger status.\\0: Not triggered\\1: Triggered
  [n+2] LEDC_TASK_TIMER{n}_CAP_ST (n=0..3) — Represents LEDC_task_timer{n}_cap trigger status.\\0: Not triggered\\1: Triggered
  [1] LEDC_TASK_DUTY_SCALE_UPDATE_CH5_ST — Represents LEDC_task_duty_scale_update_ch5 trigger status.\\0: Not triggered\\1: Triggered
  [0] LEDC_TASK_DUTY_SCALE_UPDATE_CH4_ST — Represents LEDC_task_duty_scale_update_ch4 trigger status.\\0: Not triggered\\1: Triggered
0x1D4 TASK_ST1_CLR wo — Tasks trigger status clear register
  [31] LEDC_TASK_GAMMA_RESTART_CH1_ST_CLR — Configures whether or not to clear LEDC_task_gamma_restart_ch1 trigger status.\\0: Invalid, No effect\\1: Clear
  [30] LEDC_TASK_GAMMA_RESTART_CH0_ST_CLR — Configures whether or not to clear LEDC_task_gamma_restart_ch0 trigger status.\\0: Invalid, No effect\\1: Clear
  [n+26] LEDC_TASK_TIMER{n}_PAUSE_ST_CLR (n=0..3) — Configures whether or not to clear LEDC_task_timer{n}_pause trigger status.\\0: Invalid, No effect\\1: Clear
  [n+22] LEDC_TASK_TIMER{n}_RESUME_ST_CLR (n=0..3) — Configures whether or not to clear LEDC_task_timer{n}_resume trigger status.\\0: Invalid, No effect\\1: Clear
  [n+18] LEDC_TASK_TIMER{n}_RST_ST_CLR (n=0..3) — Configures whether or not to clear LEDC_task_timer{n}_rst trigger status.\\0: Invalid, No effect\\1: Clear
  [n+12] LEDC_TASK_OVF_CNT_RST_CH{n}_ST_CLR (n=0..5) — Configures whether or not to clear LEDC_task_ovf_cnt_rst_ch{n} trigger status.\\0: Invalid, No effect\\1: Clear
  [n+6] LEDC_TASK_SIG_OUT_DIS_CH{n}_ST_CLR (n=0..5) — Configures whether or not to clear LEDC_task_sig_out_dis_ch{n} trigger status.\\0: Invalid, No effect\\1: Clear
  [n+2] LEDC_TASK_TIMER{n}_CAP_ST_CLR (n=0..3) — Configures whether or not to clear LEDC_task_timer{n}_cap trigger status.\\0: Invalid, No effect\\1: Clear
  [1] LEDC_TASK_DUTY_SCALE_UPDATE_CH5_ST_CLR — Configures whether or not to clear LEDC_task_duty_scale_update_ch5 trigger status.\\0: Invalid, No effect\\1: Clear
  [0] LEDC_TASK_DUTY_SCALE_UPDATE_CH4_ST_CLR — Configures whether or not to clear LEDC_task_duty_scale_update_ch4 trigger status.\\0: Invalid, No effect\\1: Clear
0x1D8 TASK_ST2 — Tasks trigger status register
  [31] TG1_TASK_CNT_START_TIMER1_ST — Represents TG1_task_cnt_start_timer1 trigger status.\\0: Not triggered\\1: Triggered
  [30] TG1_TASK_CNT_CAP_TIMER0_ST — Represents TG1_task_cnt_cap_timer0 trigger status.\\0: Not triggered\\1: Triggered
  [29] TG1_TASK_CNT_RELOAD_TIMER0_ST — Represents TG1_task_cnt_reload_timer0 trigger status.\\0: Not triggered\\1: Triggered
  [28] TG1_TASK_CNT_STOP_TIMER0_ST — Represents TG1_task_cnt_stop_timer0 trigger status.\\0: Not triggered\\1: Triggered
  [27] TG1_TASK_ALARM_START_TIMER0_ST — Represents TG1_task_alarm_start_timer0 trigger status.\\0: Not triggered\\1: Triggered
  [26] TG1_TASK_CNT_START_TIMER0_ST — Represents TG1_task_cnt_start_timer0 trigger status.\\0: Not triggered\\1: Triggered
  [25] TG0_TASK_CNT_CAP_TIMER1_ST — Represents TG0_task_cnt_cap_timer1 trigger status.\\0: Not triggered\\1: Triggered
  [24] TG0_TASK_CNT_RELOAD_TIMER1_ST — Represents TG0_task_cnt_reload_timer1 trigger status.\\0: Not triggered\\1: Triggered
  [23] TG0_TASK_CNT_STOP_TIMER1_ST — Represents TG0_task_cnt_stop_timer1 trigger status.\\0: Not triggered\\1: Triggered
  [22] TG0_TASK_ALARM_START_TIMER1_ST — Represents TG0_task_alarm_start_timer1 trigger status.\\0: Not triggered\\1: Triggered
  [21] TG0_TASK_CNT_START_TIMER1_ST — Represents TG0_task_cnt_start_timer1 trigger status.\\0: Not triggered\\1: Triggered
  [20] TG0_TASK_CNT_CAP_TIMER0_ST — Represents TG0_task_cnt_cap_timer0 trigger status.\\0: Not triggered\\1: Triggered
  [19] TG0_TASK_CNT_RELOAD_TIMER0_ST — Represents TG0_task_cnt_reload_timer0 trigger status.\\0: Not triggered\\1: Triggered
  [18] TG0_TASK_CNT_STOP_TIMER0_ST — Represents TG0_task_cnt_stop_timer0 trigger status.\\0: Not triggered\\1: Triggered
  [17] TG0_TASK_ALARM_START_TIMER0_ST — Represents TG0_task_alarm_start_timer0 trigger status.\\0: Not triggered\\1: Triggered
  [16] TG0_TASK_CNT_START_TIMER0_ST — Represents TG0_task_cnt_start_timer0 trigger status.\\0: Not triggered\\1: Triggered
  [n+10] LEDC_TASK_GAMMA_RESUME_CH{n}_ST (n=0..5) — Represents LEDC_task_gamma_resume_ch{n} trigger status.\\0: Not triggered\\1: Triggered
  [n+4] LEDC_TASK_GAMMA_PAUSE_CH{n}_ST (n=0..5) — Represents LEDC_task_gamma_pause_ch{n} trigger status.\\0: Not triggered\\1: Triggered
  [n-2] LEDC_TASK_GAMMA_RESTART_CH{n}_ST (n=2..5) — Represents LEDC_task_gamma_restart_ch{n} trigger status.\\0: Not triggered\\1: Triggered
0x1DC TASK_ST2_CLR wo — Tasks trigger status clear register
  [31] TG1_TASK_CNT_START_TIMER1_ST_CLR — Configures whether or not to clear TG1_task_cnt_start_timer1 trigger status.\\0: Invalid, No effect\\1: Clear
  [30] TG1_TASK_CNT_CAP_TIMER0_ST_CLR — Configures whether or not to clear TG1_task_cnt_cap_timer0 trigger status.\\0: Invalid, No effect\\1: Clear
  [29] TG1_TASK_CNT_RELOAD_TIMER0_ST_CLR — Configures whether or not to clear TG1_task_cnt_reload_timer0 trigger status.\\0: Invalid, No effect\\1: Clear
  [28] TG1_TASK_CNT_STOP_TIMER0_ST_CLR — Configures whether or not to clear TG1_task_cnt_stop_timer0 trigger status.\\0: Invalid, No effect\\1: Clear
  [27] TG1_TASK_ALARM_START_TIMER0_ST_CLR — Configures whether or not to clear TG1_task_alarm_start_timer0 trigger status.\\0: Invalid, No effect\\1: Clear
  [26] TG1_TASK_CNT_START_TIMER0_ST_CLR — Configures whether or not to clear TG1_task_cnt_start_timer0 trigger status.\\0: Invalid, No effect\\1: Clear
  [25] TG0_TASK_CNT_CAP_TIMER1_ST_CLR — Configures whether or not to clear TG0_task_cnt_cap_timer1 trigger status.\\0: Invalid, No effect\\1: Clear
  [24] TG0_TASK_CNT_RELOAD_TIMER1_ST_CLR — Configures whether or not to clear TG0_task_cnt_reload_timer1 trigger status.\\0: Invalid, No effect\\1: Clear
  [23] TG0_TASK_CNT_STOP_TIMER1_ST_CLR — Configures whether or not to clear TG0_task_cnt_stop_timer1 trigger status.\\0: Invalid, No effect\\1: Clear
  [22] TG0_TASK_ALARM_START_TIMER1_ST_CLR — Configures whether or not to clear TG0_task_alarm_start_timer1 trigger status.\\0: Invalid, No effect\\1: Clear
  [21] TG0_TASK_CNT_START_TIMER1_ST_CLR — Configures whether or not to clear TG0_task_cnt_start_timer1 trigger status.\\0: Invalid, No effect\\1: Clear
  [20] TG0_TASK_CNT_CAP_TIMER0_ST_CLR — Configures whether or not to clear TG0_task_cnt_cap_timer0 trigger status.\\0: Invalid, No effect\\1: Clear
  [19] TG0_TASK_CNT_RELOAD_TIMER0_ST_CLR — Configures whether or not to clear TG0_task_cnt_reload_timer0 trigger status.\\0: Invalid, No effect\\1: Clear
  [18] TG0_TASK_CNT_STOP_TIMER0_ST_CLR — Configures whether or not to clear TG0_task_cnt_stop_timer0 trigger status.\\0: Invalid, No effect\\1: Clear
  [17] TG0_TASK_ALARM_START_TIMER0_ST_CLR — Configures whether or not to clear TG0_task_alarm_start_timer0 trigger status.\\0: Invalid, No effect\\1: Clear
  [16] TG0_TASK_CNT_START_TIMER0_ST_CLR — Configures whether or not to clear TG0_task_cnt_start_timer0 trigger status.\\0: Invalid, No effect\\1: Clear
  [n+10] LEDC_TASK_GAMMA_RESUME_CH{n}_ST_CLR (n=0..5) — Configures whether or not to clear LEDC_task_gamma_resume_ch{n} trigger status.\\0: Invalid, No effect\\1: Clear
  [n+4] LEDC_TASK_GAMMA_PAUSE_CH{n}_ST_CLR (n=0..5) — Configures whether or not to clear LEDC_task_gamma_pause_ch{n} trigger status.\\0: Invalid, No effect\\1: Clear
  [n-2] LEDC_TASK_GAMMA_RESTART_CH{n}_ST_CLR (n=2..5) — Configures whether or not to clear LEDC_task_gamma_restart_ch{n} trigger status.\\0: Invalid, No effect\\1: Clear
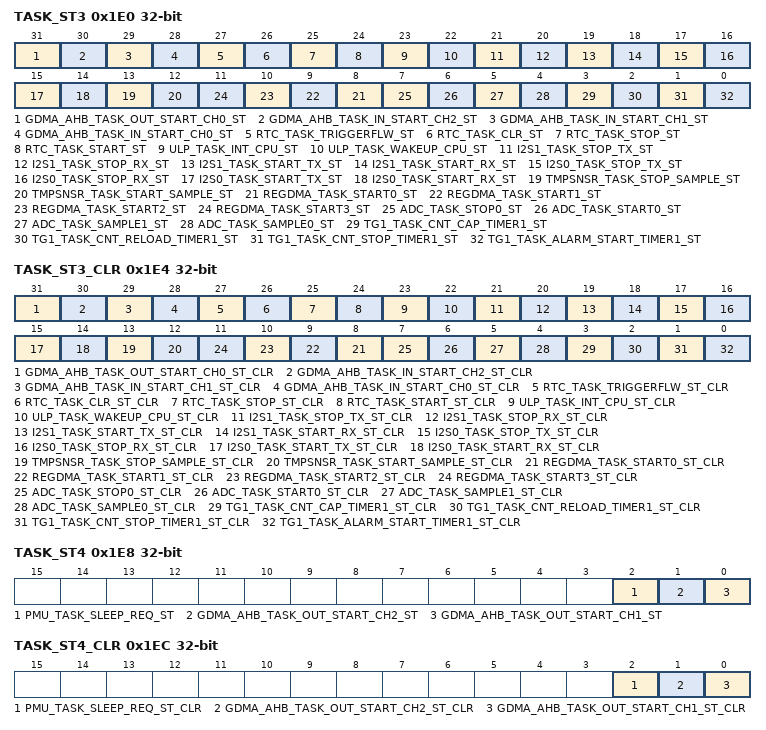
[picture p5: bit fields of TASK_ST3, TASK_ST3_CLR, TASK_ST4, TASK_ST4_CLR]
0x1E0 TASK_ST3 — Tasks trigger status register
  [31] GDMA_AHB_TASK_OUT_START_CH0_ST — Represents GDMA_AHB_task_out_start_ch0 trigger status.\\0: Not triggered\\1: Triggered
  [30] GDMA_AHB_TASK_IN_START_CH2_ST — Represents GDMA_AHB_task_in_start_ch2 trigger status.\\0: Not triggered\\1: Triggered
  [29] GDMA_AHB_TASK_IN_START_CH1_ST — Represents GDMA_AHB_task_in_start_ch1 trigger status.\\0: Not triggered\\1: Triggered
  [28] GDMA_AHB_TASK_IN_START_CH0_ST — Represents GDMA_AHB_task_in_start_ch0 trigger status.\\0: Not triggered\\1: Triggered
  [27] RTC_TASK_TRIGGERFLW_ST — Represents RTC_task_triggerflw trigger status.\\0: Not triggered\\1: Triggered
  [26] RTC_TASK_CLR_ST — Represents RTC_task_clr trigger status.\\0: Not triggered\\1: Triggered
  [25] RTC_TASK_STOP_ST — Represents RTC_task_stop trigger status.\\0: Not triggered\\1: Triggered
  [24] RTC_TASK_START_ST — Represents RTC_task_start trigger status.\\0: Not triggered\\1: Triggered
  [23] ULP_TASK_INT_CPU_ST — Represents ULP_task_int_cpu trigger status.\\0: Not triggered\\1: Triggered
  [22] ULP_TASK_WAKEUP_CPU_ST — Represents ULP_task_wakeup_cpu trigger status.\\0: Not triggered\\1: Triggered
  [21] I2S1_TASK_STOP_TX_ST — Represents I2S1_task_stop_tx trigger status.\\0: Not triggered\\1: Triggered
  [20] I2S1_TASK_STOP_RX_ST — Represents I2S1_task_stop_rx trigger status.\\0: Not triggered\\1: Triggered
  [19] I2S1_TASK_START_TX_ST — Represents I2S1_task_start_tx trigger status.\\0: Not triggered\\1: Triggered
  [18] I2S1_TASK_START_RX_ST — Represents I2S1_task_start_rx trigger status.\\0: Not triggered\\1: Triggered
  [17] I2S0_TASK_STOP_TX_ST — Represents I2S0_task_stop_tx trigger status.\\0: Not triggered\\1: Triggered
  [16] I2S0_TASK_STOP_RX_ST — Represents I2S0_task_stop_rx trigger status.\\0: Not triggered\\1: Triggered
  [15] I2S0_TASK_START_TX_ST — Represents I2S0_task_start_tx trigger status.\\0: Not triggered\\1: Triggered
  [14] I2S0_TASK_START_RX_ST — Represents I2S0_task_start_rx trigger status.\\0: Not triggered\\1: Triggered
  [13] TMPSNSR_TASK_STOP_SAMPLE_ST — Represents TMPSNSR_task_stop_sample trigger status.\\0: Not triggered\\1: Triggered
  [12] TMPSNSR_TASK_START_SAMPLE_ST — Represents TMPSNSR_task_start_sample trigger status.\\0: Not triggered\\1: Triggered
  [n+8] REGDMA_TASK_START{n}_ST (n=0..3) — Represents REGDMA_task_start{n} trigger status.\\0: Not triggered\\1: Triggered
  [7] ADC_TASK_STOP0_ST — Represents ADC_task_stop0 trigger status.\\0: Not triggered\\1: Triggered
  [6] ADC_TASK_START0_ST — Represents ADC_task_start0 trigger status.\\0: Not triggered\\1: Triggered
  [5] ADC_TASK_SAMPLE1_ST — Represents ADC_task_sample1 trigger status.\\0: Not triggered\\1: Triggered
  [4] ADC_TASK_SAMPLE0_ST — Represents ADC_task_sample0 trigger status.\\0: Not triggered\\1: Triggered
  [3] TG1_TASK_CNT_CAP_TIMER1_ST — Represents TG1_task_cnt_cap_timer1 trigger status.\\0: Not triggered\\1: Triggered
  [2] TG1_TASK_CNT_RELOAD_TIMER1_ST — Represents TG1_task_cnt_reload_timer1 trigger status.\\0: Not triggered\\1: Triggered
  [1] TG1_TASK_CNT_STOP_TIMER1_ST — Represents TG1_task_cnt_stop_timer1 trigger status.\\0: Not triggered\\1: Triggered
  [0] TG1_TASK_ALARM_START_TIMER1_ST — Represents TG1_task_alarm_start_timer1 trigger status.\\0: Not triggered\\1: Triggered
0x1E4 TASK_ST3_CLR wo — Tasks trigger status clear register
  [31] GDMA_AHB_TASK_OUT_START_CH0_ST_CLR — Configures whether or not to clear GDMA_AHB_task_out_start_ch0 trigger status.\\0: Invalid, No effect\\1: Clear
  [30] GDMA_AHB_TASK_IN_START_CH2_ST_CLR — Configures whether or not to clear GDMA_AHB_task_in_start_ch2 trigger status.\\0: Invalid, No effect\\1: Clear
  [29] GDMA_AHB_TASK_IN_START_CH1_ST_CLR — Configures whether or not to clear GDMA_AHB_task_in_start_ch1 trigger status.\\0: Invalid, No effect\\1: Clear
  [28] GDMA_AHB_TASK_IN_START_CH0_ST_CLR — Configures whether or not to clear GDMA_AHB_task_in_start_ch0 trigger status.\\0: Invalid, No effect\\1: Clear
  [27] RTC_TASK_TRIGGERFLW_ST_CLR — Configures whether or not to clear RTC_task_triggerflw trigger status.\\0: Invalid, No effect\\1: Clear
  [26] RTC_TASK_CLR_ST_CLR — Configures whether or not to clear RTC_task_clr trigger status.\\0: Invalid, No effect\\1: Clear
  [25] RTC_TASK_STOP_ST_CLR — Configures whether or not to clear RTC_task_stop trigger status.\\0: Invalid, No effect\\1: Clear
  [24] RTC_TASK_START_ST_CLR — Configures whether or not to clear RTC_task_start trigger status.\\0: Invalid, No effect\\1: Clear
  [23] ULP_TASK_INT_CPU_ST_CLR — Configures whether or not to clear ULP_task_int_cpu trigger status.\\0: Invalid, No effect\\1: Clear
  [22] ULP_TASK_WAKEUP_CPU_ST_CLR — Configures whether or not to clear ULP_task_wakeup_cpu trigger status.\\0: Invalid, No effect\\1: Clear
  [21] I2S1_TASK_STOP_TX_ST_CLR — Configures whether or not to clear I2S1_task_stop_tx trigger status.\\0: Invalid, No effect\\1: Clear
  [20] I2S1_TASK_STOP_RX_ST_CLR — Configures whether or not to clear I2S1_task_stop_rx trigger status.\\0: Invalid, No effect\\1: Clear
  [19] I2S1_TASK_START_TX_ST_CLR — Configures whether or not to clear I2S1_task_start_tx trigger status.\\0: Invalid, No effect\\1: Clear
  [18] I2S1_TASK_START_RX_ST_CLR — Configures whether or not to clear I2S1_task_start_rx trigger status.\\0: Invalid, No effect\\1: Clear
  [17] I2S0_TASK_STOP_TX_ST_CLR — Configures whether or not to clear I2S0_task_stop_tx trigger status.\\0: Invalid, No effect\\1: Clear
  [16] I2S0_TASK_STOP_RX_ST_CLR — Configures whether or not to clear I2S0_task_stop_rx trigger status.\\0: Invalid, No effect\\1: Clear
  [15] I2S0_TASK_START_TX_ST_CLR — Configures whether or not to clear I2S0_task_start_tx trigger status.\\0: Invalid, No effect\\1: Clear
  [14] I2S0_TASK_START_RX_ST_CLR — Configures whether or not to clear I2S0_task_start_rx trigger status.\\0: Invalid, No effect\\1: Clear
  [13] TMPSNSR_TASK_STOP_SAMPLE_ST_CLR — Configures whether or not to clear TMPSNSR_task_stop_sample trigger status.\\0: Invalid, No effect\\1: Clear
  [12] TMPSNSR_TASK_START_SAMPLE_ST_CLR — Configures whether or not to clear TMPSNSR_task_start_sample trigger status.\\0: Invalid, No effect\\1: Clear
  [n+8] REGDMA_TASK_START{n}_ST_CLR (n=0..3) — Configures whether or not to clear REGDMA_task_start{n} trigger status.\\0: Invalid, No effect\\1: Clear
  [7] ADC_TASK_STOP0_ST_CLR — Configures whether or not to clear ADC_task_stop0 trigger status.\\0: Invalid, No effect\\1: Clear
  [6] ADC_TASK_START0_ST_CLR — Configures whether or not to clear ADC_task_start0 trigger status.\\0: Invalid, No effect\\1: Clear
  [5] ADC_TASK_SAMPLE1_ST_CLR — Configures whether or not to clear ADC_task_sample1 trigger status.\\0: Invalid, No effect\\1: Clear
  [4] ADC_TASK_SAMPLE0_ST_CLR — Configures whether or not to clear ADC_task_sample0 trigger status.\\0: Invalid, No effect\\1: Clear
  [3] TG1_TASK_CNT_CAP_TIMER1_ST_CLR — Configures whether or not to clear TG1_task_cnt_cap_timer1 trigger status.\\0: Invalid, No effect\\1: Clear
  [2] TG1_TASK_CNT_RELOAD_TIMER1_ST_CLR — Configures whether or not to clear TG1_task_cnt_reload_timer1 trigger status.\\0: Invalid, No effect\\1: Clear
  [1] TG1_TASK_CNT_STOP_TIMER1_ST_CLR — Configures whether or not to clear TG1_task_cnt_stop_timer1 trigger status.\\0: Invalid, No effect\\1: Clear
  [0] TG1_TASK_ALARM_START_TIMER1_ST_CLR — Configures whether or not to clear TG1_task_alarm_start_timer1 trigger status.\\0: Invalid, No effect\\1: Clear
0x1E8 TASK_ST4 — Tasks trigger status register
  [2] PMU_TASK_SLEEP_REQ_ST — Represents PMU_task_sleep_req trigger status.\\0: Not triggered\\1: Triggered
  [1] GDMA_AHB_TASK_OUT_START_CH2_ST — Represents GDMA_AHB_task_out_start_ch2 trigger status.\\0: Not triggered\\1: Triggered
  [0] GDMA_AHB_TASK_OUT_START_CH1_ST — Represents GDMA_AHB_task_out_start_ch1 trigger status.\\0: Not triggered\\1: Triggered
0x1EC TASK_ST4_CLR wo — Tasks trigger status clear register
  [2] PMU_TASK_SLEEP_REQ_ST_CLR — Configures whether or not to clear PMU_task_sleep_req trigger status.\\0: Invalid, No effect\\1: Clear
  [1] GDMA_AHB_TASK_OUT_START_CH2_ST_CLR — Configures whether or not to clear GDMA_AHB_task_out_start_ch2 trigger status.\\0: Invalid, No effect\\1: Clear
  [0] GDMA_AHB_TASK_OUT_START_CH1_ST_CLR — Configures whether or not to clear GDMA_AHB_task_out_start_ch1 trigger status.\\0: Invalid, No effect\\1: Clear
0x1F0 CLK_EN — ETM clock enable register
  [0] CLK_EN — Configures whether or not to open register clock gate.\\0: Open the clock gate only when application writes registers\\1: Force open the clock gate for register
0x1F4 DATE — ETM date register
